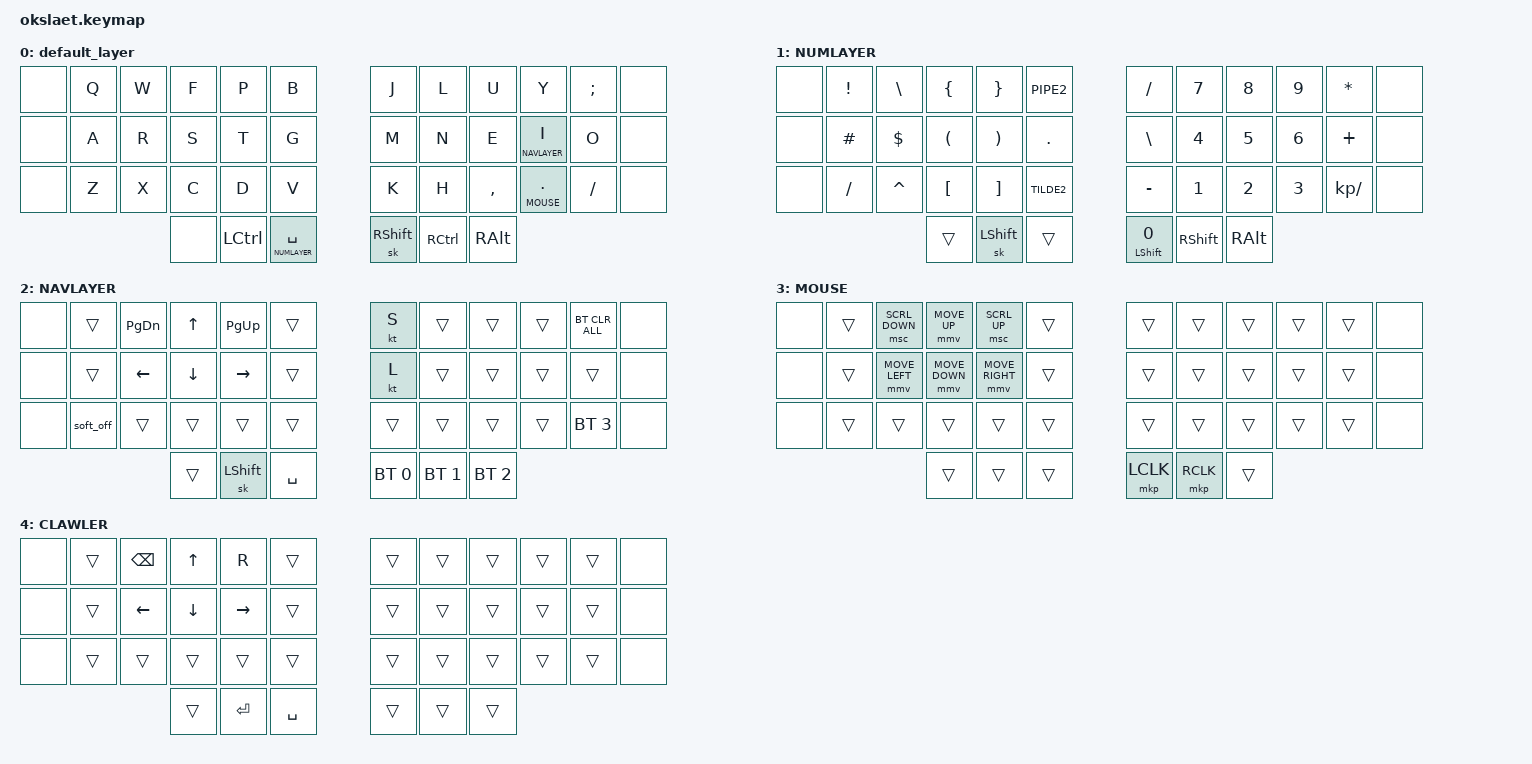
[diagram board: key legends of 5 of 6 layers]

#include <behaviors.dtsi>
#include <dt-bindings/zmk/keys.h>
#include <dt-bindings/zmk/bt.h>

#define ZMK_POINTING_DEFAULT_MOVE_VAL 3000  // default: 600
#define ZMK_POINTING_DEFAULT_SCRL_VAL 40    // default: 10

#include <dt-bindings/zmk/pointing.h>

#define DEFAULT      0
#define NUMLAYER     1
#define NAVLAYER     2
#define MOUSE        3
#define CLAWLER      4
#define BOOT         5

/*          42 KEY MATRIX / LAYOUT MAPPING (only using 36)
  ╭────────────────────────┬────────────────────────╮ 
  │  0   1   2   3   4   5 │  6   7   8   9  10  11 │ 
  │ 12  13  14  15 (16) 17 │ 18 (19) 20  21  22  23 │ 
  │ 24  25  26  27  28  29 │ 30  31  32  33  34  35 │ 
  ╰───────────╮ 36  37  38 │ 39  40  41 ╭───────────╯ 
              ╰────────────┴────────────╯            */

/ {
     behaviors {
        nbspc: n_bspc {
            compatible = "zmk,behavior-mod-morph";
            #binding-cells = <0>;
            bindings = <&kp N>, <&kp BSPC>;
            mods = <(MOD_LCTL|MOD_RALT)>;
        };
    };
    
    combos {
        compatible = "zmk,combos";
        combo_esc {
            timeout-ms = <50>;
            key-positions = <1 2>;
            bindings = <&kp ESC>;
        };
        combo_ent {
            timeout-ms = <50>;
            key-positions = <31 32>;
            bindings = <&kp RET>;
        };
        combo_bspc {
            timeout-ms = <50>;
            key-positions = <19 20>;
            bindings = <&kp BSPC>;
        };
        combo_tab {
            timeout-ms = <50>;
            key-positions = <3 4>;
            bindings = <&kp TAB>;
        };
        combo_quote {
            timeout-ms = <50>;
            key-positions = <7 8>;
            bindings = <&kp SQT>;
        };
        combo_lclk {
            timeout-ms = <50>;
            key-positions = <15 16>;
            bindings = <&mkp MB1>;
        };
        combo_rclk {
            timeout-ms = <50>;
            key-positions = <14 15>;
            bindings = <&mkp MB2>;
        };
        combo_del {
            timeout-ms = <50>;
            key-positions = <27 28>;
            bindings = <&kp DEL>;
        };
        combo_clawler {
            timeout-ms = <50>;
            key-positions = <1 2 3>;
            bindings = <&tog CLAWLER>;
        };
        combo_boot {
            timeout-ms = <50>;
            key-positions = <30 31 32>;
            bindings = <&tog BOOT>;
        };
        combo_lgui {
            timeout-ms = <50>;
            key-positions = <26 27>;
            bindings = <&kp LGUI>;
        };
        combo_equal {
            timeout-ms = <50>;
            key-positions = <2 3>;
            bindings = <&kp EQUAL>;
        };
        combo_fslh {
            timeout-ms = <50>;
            key-positions = <20 21>;
            bindings = <&kp FSLH>;
        };

    };
};

/ {
        keymap {
                compatible = "zmk,keymap";
                default_layer {

                        bindings = <
                    &none    &kp Q &kp W &kp F &kp P &kp B              &kp J &kp L     &kp U     &kp Y               &kp SEMI     &none
                    &none    &kp A &kp R &kp S &kp T &kp G              &kp M &kp N     &kp E     &lt NAVLAYER I      &kp O        &none
                    &none    &kp Z &kp X &kp C &kp D &kp V              &kp K &kp H     &kp COMMA &lt MOUSE DOT       &kp FSLH     &none

                    /**/  &none &kp LCTRL &lt NUMLAYER SPACE     /**/        &sk RSHIFT &kp RCTRL &kp RALT   /**/
                  
                        >;
                };
                NUMLAYER {

                        bindings = <
            &none   &kp EXCL &kp BSLH   &kp LBRC &kp RBRC &kp PIPE2                 &kp FSLH    &kp N7  &kp N8     &kp N9   &kp ASTRK          &none
            &none   &kp HASH &kp DLLR   &kp LPAR &kp RPAR &kp DOT                   &kp BSLH    &kp N4  &kp N5     &kp N6   &kp PLUS           &none
            &none   &kp FSLH &kp CARET  &kp LBKT &kp RBKT &kp TILDE2                &kp MINUS   &kp N1  &kp N2     &kp N3   &kp KP_DIVIDE      &none
                                            &trans &sk LSHIFT &trans           &mt LSHIFT NUMBER_0    &kp RSHIFT  &kp RALT
                  
                        >;
                };
                NAVLAYER {

                        bindings = <
            &none  &trans       &kp PG_DN   &kp UP      &kp PG_UP   &trans              &kt S   &trans  &trans  &trans  &bt BT_CLR_ALL  &none
            &none  &trans       &kp LEFT    &kp DOWN    &kp RIGHT   &trans              &kt L   &trans  &trans  &trans  &trans          &none
            &none  &soft_off    &trans      &trans      &trans      &trans              &trans   &trans  &trans  &trans  &bt BT_SEL 3    &none
                                                 &trans &sk LSHIFT &kp SPACE     &bt BT_SEL 0 &bt BT_SEL 1 &bt BT_SEL 2
                  
                        >;
                };
                MOUSE {

                        bindings = <
            &none  &trans  &msc SCRL_DOWN      &mmv MOVE_UP    &msc SCRL_UP        &trans              &trans   &trans  &trans  &trans  &trans &none
            &none  &trans  &mmv MOVE_LEFT      &mmv MOVE_DOWN  &mmv MOVE_RIGHT     &trans              &trans      &trans  &trans  &trans  &trans &none
            &none  &trans    &trans              &trans          &trans              &trans              &trans      &trans  &trans  &trans  &trans &none
                                        &trans &trans &trans                                    &mkp LCLK &mkp RCLK &trans                  
                        >;
                };


    
                CLAWLER {

                        bindings = <
   &none    &trans &kp BSPC     &kp UP      &kp R       &trans              &trans   &trans     &trans    &trans   &trans     &none 
   &none    &trans &kp LEFT     &kp DOWN    &kp RIGHT   &trans              &trans   &trans     &trans    &trans   &trans     &none 
   &none    &trans &trans       &trans      &trans      &trans              &trans   &trans     &trans    &trans   &trans     &none  

                          &trans &kp RET &kp SPACE                                     &trans &trans &trans
                  
                        >;
                };
                BOOT {

                        bindings = <
            &none  &bootloader  &bootloader &bootloader &bootloader &bootloader             &bootloader  &bootloader &bootloader &bootloader &bootloader &none
            &none  &kp K_SLEEP  &kp K_SLEEP  &kp K_SLEEP  &kp K_SLEEP  &kp K_SLEEP          &kp K_SLEEP  &kp K_SLEEP  &kp K_SLEEP  &kp K_SLEEP  &kp K_SLEEP  &none
            &none  &soft_off  &soft_off &soft_off &soft_off &soft_off                        &trans  &trans  &trans &soft_off &soft_off 
                                                                &trans &trans &trans         &trans &trans &trans                  
                        >;
                };

        };
};

/* You will never find what you seek... Stop Looking */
